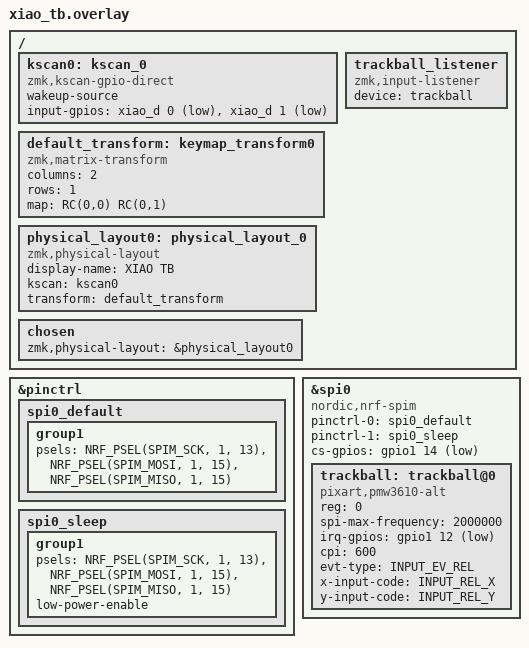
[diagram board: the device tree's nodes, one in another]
#include <dt-bindings/zmk/matrix_transform.h>
#include <dt-bindings/gpio/gpio.h>
#include <zephyr/dt-bindings/input/input-event-codes.h>

/ {
    kscan0: kscan_0 {
        compatible = "zmk,kscan-gpio-direct";
        wakeup-source;
        input-gpios
            = <&xiao_d 0 (GPIO_ACTIVE_LOW | GPIO_PULL_UP)>
            , <&xiao_d 1 (GPIO_ACTIVE_LOW | GPIO_PULL_UP)>
            ;
    };

    default_transform: keymap_transform0 {
        compatible = "zmk,matrix-transform";
        columns = <2>;
        rows = <1>;
        map = <
            RC(0,0) RC(0,1)
        >;
    };

    physical_layout0: physical_layout_0 {
        compatible = "zmk,physical-layout";
        display-name = "XIAO TB";
        kscan = <&kscan0>;
        transform = <&default_transform>;
    };

    chosen {
        zmk,physical-layout = &physical_layout0;
    };

    trackball_listener {
        compatible = "zmk,input-listener";
        device = <&trackball>;
    };
};

&pinctrl {
    spi0_default: spi0_default {
        group1 {
            psels = <NRF_PSEL(SPIM_SCK, 1, 13)>,
                <NRF_PSEL(SPIM_MOSI, 1, 15)>,
                <NRF_PSEL(SPIM_MISO, 1, 15)>;
        };
    };

    spi0_sleep: spi0_sleep {
        group1 {
            psels = <NRF_PSEL(SPIM_SCK, 1, 13)>,
                <NRF_PSEL(SPIM_MOSI, 1, 15)>,
                <NRF_PSEL(SPIM_MISO, 1, 15)>;
            low-power-enable;
        };
    };
};

&spi0 {
    status = "okay";
    compatible = "nordic,nrf-spim";
    pinctrl-0 = <&spi0_default>;
    pinctrl-1 = <&spi0_sleep>;
    pinctrl-names = "default", "sleep";
    cs-gpios = <&gpio1 14 GPIO_ACTIVE_LOW>;

    trackball: trackball@0 {
        status = "okay";
        compatible = "pixart,pmw3610-alt";
        reg = <0>;
        spi-max-frequency = <2000000>;
        irq-gpios = <&gpio1 12 (GPIO_ACTIVE_LOW | GPIO_PULL_UP)>;
        cpi = <600>;
        evt-type = <INPUT_EV_REL>;
        x-input-code = <INPUT_REL_X>;
        y-input-code = <INPUT_REL_Y>;
    };
};
